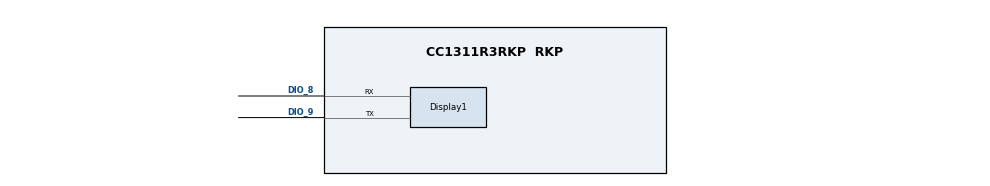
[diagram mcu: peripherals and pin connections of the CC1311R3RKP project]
/**
 * @cliArgs --device "CC1311R3RKP" --part "Default" --package "RKP" --rtos "nortos" --product "simplelink_cc13xx_cc26xx_sdk@8.30.01.01"
 * @versions {"tool":"1.21.1+3772"}
 */

/**
 * Import the modules used in this configuration.
 */
const CCFG     = scripting.addModule("/ti/devices/CCFG");
const custom   = scripting.addModule("/ti/devices/radioconfig/custom");
const rfdesign = scripting.addModule("/ti/devices/radioconfig/rfdesign");
const Display  = scripting.addModule("/ti/display/Display", {}, false);
const Display1 = Display.addInstance();
const Board    = scripting.addModule("/ti/drivers/Board");
const GPIO     = scripting.addModule("/ti/drivers/GPIO");
const RF       = scripting.addModule("/ti/drivers/RF");

/**
 * Write custom configuration values to the imported modules.
 */
CCFG.xoscCapArrayDelta       = 0xC1;
CCFG.dioBootloaderBackdoor   = 15;
CCFG.levelBootloaderBackdoor = "Active low";
CCFG.ccfgTemplate.$name      = "ti_devices_CCFG_CCFGCC26XXTemplate0";

custom.prop8                                       = ["custom868"];
custom.radioConfigcustom868.$name                  = "ti_devices_radioconfig_settings_prop0";
custom.radioConfigcustom868.symbolRate             = 250.000;
custom.radioConfigcustom868.txPower                = "10";
custom.radioConfigcustom868.whitening              = "CC1101/CC2500 compatible";
custom.radioConfigcustom868.syncWord               = 0xD391D391;
custom.radioConfigcustom868.deviation              = 165.0;
custom.radioConfigcustom868.rxFilterBw             = "621.6";
custom.radioConfigcustom868.carrierFrequency       = 863.9900;
custom.radioConfigcustom868.codeExportConfig.$name = "ti_devices_radioconfig_code_export_param0";

Display1.$name                   = "CONFIG_Display_0";
Display1.baudRate                = 921600;
Display1.uartBufferSize          = 8196;
Display1.uart.$name              = "CONFIG_UART2_1";
Display1.uart.uart.txPin.$assign = "DIO_9";
Display1.uart.uart.rxPin.$assign = "DIO_8";

Board.generateInitializationFunctions = false;

/**
 * Pinmux solution for unlocked pins/peripherals. This ensures that minor changes to the automatic solver in a future
 * version of the tool will not impact the pinmux you originally saw.  These lines can be completely deleted in order to
 * re-solve from scratch.
 */
Display1.uart.uart.$suggestSolution = "UART0";
